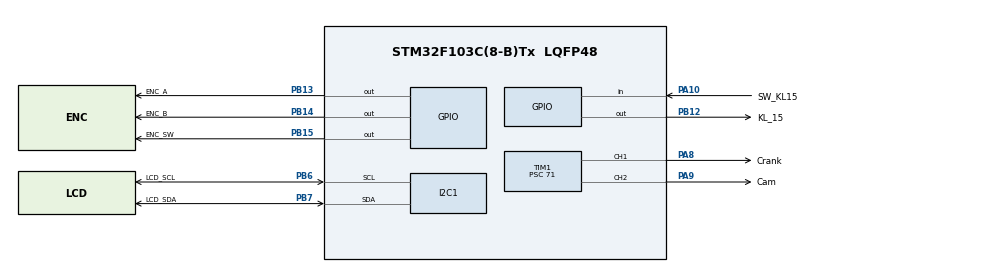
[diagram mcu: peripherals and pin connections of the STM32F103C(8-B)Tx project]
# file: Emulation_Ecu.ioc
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Mcu.Family=STM32F1
Mcu.Name=STM32F103C(8-B)Tx
Mcu.Package=LQFP48
NVIC.PriorityGroup=NVIC_PRIORITYGROUP_4
NVIC.TIM1_UP_IRQn=true\:0\:0\:false\:false\:true\:true\:true\:true
NVIC.TIM4_IRQn=true\:15\:0\:false\:false\:true\:false\:true\:true
NVIC.TimeBase=TIM4_IRQn
NVIC.TimeBaseIP=TIM4
PA10.GPIO_Label=SW_KL15
PA10.Signal=GPIO_Input
PA13.Mode=Serial_Wire
PA13.Signal=SYS_JTMS-SWDIO
PA14.Mode=Serial_Wire
PA14.Signal=SYS_JTCK-SWCLK
PA8.GPIO_Label=Crank
PA8.Signal=S_TIM1_CH1
PA9.GPIO_Label=Cam
PA9.Signal=S_TIM1_CH2
PB12.GPIO_Label=KL_15
PB12.GPIO_PuPd=GPIO_PULLUP
PB12.Signal=GPIO_Output
PB13.GPIO_Label=ENC_A
PB13.GPIO_PuPd=GPIO_PULLUP
PB13.Signal=GPIO_Output
PB14.GPIO_Label=ENC_B
PB14.GPIO_PuPd=GPIO_PULLUP
PB14.Signal=GPIO_Output
PB15.GPIO_Label=ENC_SW
PB15.GPIO_PuPd=GPIO_PULLUP
PB15.Signal=GPIO_Output
PB6.GPIO_Label=LCD_SCL
PB6.Mode=I2C
PB6.Signal=I2C1_SCL
PB7.GPIO_Label=LCD_SDA
PB7.Mode=I2C
PB7.Signal=I2C1_SDA
ProjectManager.HeapSize=0x200
ProjectManager.StackSize=0x400
ProjectManager.TargetToolchain=STM32CubeIDE
RCC.APB1Freq_Value=8000000
RCC.APB2Freq_Value=8000000
RCC.APB2TimFreq_Value=8000000
SH.S_TIM1_CH1.0=TIM1_CH1,PWM Generation1 CH1
SH.S_TIM1_CH2.0=TIM1_CH2,PWM Generation2 CH2
TIM1.AutoReloadPreload=TIM_AUTORELOAD_PRELOAD_ENABLE
TIM1.Channel-PWM\ Generation1\ CH1=TIM_CHANNEL_1
TIM1.Channel-PWM\ Generation2\ CH2=TIM_CHANNEL_2
TIM1.Period=999
TIM1.Prescaler=71
VP_SYS_VS_tim4.Mode=TIM4
VP_TIM1_VS_ClockSourceINT.Mode=Internal
board=custom

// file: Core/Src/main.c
/* USER CODE BEGIN Header */
/**
  ******************************************************************************
  * @file           : main.c
  * @brief          : Main program body
  ******************************************************************************
  * @attention
  *
  * Copyright (c) 2026 STMicroelectronics.
  * All rights reserved.
  *
  * This software is licensed under terms that can be found in the LICENSE file
  * in the root directory of this software component.
  * If no LICENSE file comes with this software, it is provided AS-IS.
  *
  ******************************************************************************
  */
/* USER CODE END Header */
#include "main.h"
#include "i2c.h"
#include "tim.h"
#include "gpio.h"

/* USER CODE BEGIN Includes */
#include "emulator_app.hpp"
/* USER CODE END Includes */

void SystemClock_Config(void);

int main(void)
{

  /* MCU Configuration--------------------------------------------------------*/

  /* Reset of all peripherals, Initializes the Flash interface and the Systick. */
  HAL_Init();

  /* Configure the system clock */
  SystemClock_Config();

  /* Initialize all configured peripherals */
  MX_GPIO_Init();
  MX_I2C1_Init();
  MX_TIM1_Init();
  /* USER CODE BEGIN 2 */
  EmulatorApp_Init();
  /* USER CODE END 2 */

  /* Infinite loop */
  while (1)
  {

    /* USER CODE BEGIN 3 */
    EmulatorApp_Run();
  }
  /* USER CODE END 3 */
}

void SystemClock_Config(void)
{
  RCC_OscInitTypeDef RCC_OscInitStruct = {0};
  RCC_ClkInitTypeDef RCC_ClkInitStruct = {0};

  /** Initializes the RCC Oscillators according to the specified parameters
  * in the RCC_OscInitTypeDef structure.
  */
  RCC_OscInitStruct.OscillatorType = RCC_OSCILLATORTYPE_HSI;
  RCC_OscInitStruct.HSIState = RCC_HSI_ON;
  RCC_OscInitStruct.HSICalibrationValue = RCC_HSICALIBRATION_DEFAULT;
  RCC_OscInitStruct.PLL.PLLState = RCC_PLL_NONE;
  if (HAL_RCC_OscConfig(&RCC_OscInitStruct) != HAL_OK)
  {
    Error_Handler();
  }

  /** Initializes the CPU, AHB and APB buses clocks
  */
  RCC_ClkInitStruct.ClockType = RCC_CLOCKTYPE_HCLK|RCC_CLOCKTYPE_SYSCLK
                              |RCC_CLOCKTYPE_PCLK1|RCC_CLOCKTYPE_PCLK2;
  RCC_ClkInitStruct.SYSCLKSource = RCC_SYSCLKSOURCE_HSI;
  RCC_ClkInitStruct.AHBCLKDivider = RCC_SYSCLK_DIV1;
  RCC_ClkInitStruct.APB1CLKDivider = RCC_HCLK_DIV1;
  RCC_ClkInitStruct.APB2CLKDivider = RCC_HCLK_DIV1;

  if (HAL_RCC_ClockConfig(&RCC_ClkInitStruct, FLASH_LATENCY_0) != HAL_OK)
  {
    Error_Handler();
  }
}

void HAL_TIM_PeriodElapsedCallback(TIM_HandleTypeDef *htim)
{
  if (htim->Instance == TIM4)
  {
    HAL_IncTick();
  }
}

void Error_Handler(void)
{
  __disable_irq();
  while (1)
  {
  }
}
